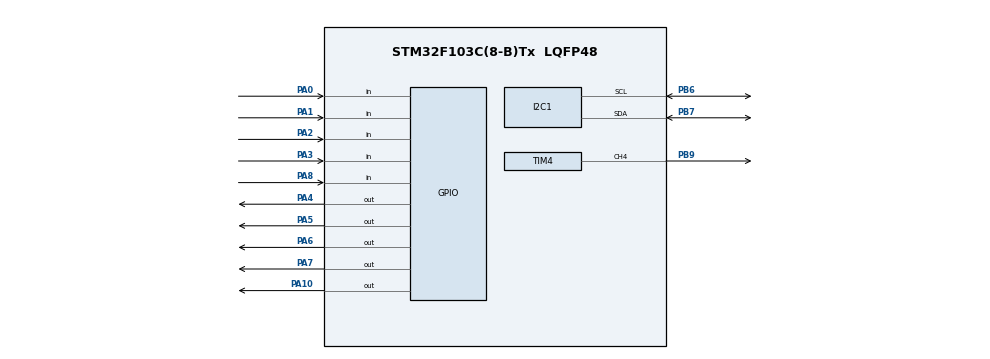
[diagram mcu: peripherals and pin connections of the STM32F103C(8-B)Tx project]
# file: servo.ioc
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I2C1.I2C_Mode=I2C_Fast
Mcu.Family=STM32F1
Mcu.Name=STM32F103C(8-B)Tx
Mcu.Package=LQFP48
NVIC.PriorityGroup=NVIC_PRIORITYGROUP_4
PA0-WKUP.GPIO_PuPd=GPIO_PULLDOWN
PA0-WKUP.Signal=GPIO_Input
PA1.GPIO_PuPd=GPIO_PULLDOWN
PA1.Signal=GPIO_Input
PA10.Signal=GPIO_Output
PA2.GPIO_PuPd=GPIO_PULLDOWN
PA2.Signal=GPIO_Input
PA3.GPIO_PuPd=GPIO_PULLDOWN
PA3.Signal=GPIO_Input
PA4.Signal=GPIO_Output
PA5.Signal=GPIO_Output
PA6.GPIO_ModeDefaultOutputPP=GPIO_MODE_OUTPUT_PP
PA6.Signal=GPIO_Output
PA7.Signal=GPIO_Output
PA8.GPIO_PuPd=GPIO_NOPULL
PA8.Signal=GPIO_Input
PB6.Mode=I2C
PB6.Signal=I2C1_SCL
PB7.Mode=I2C
PB7.Signal=I2C1_SDA
PB9.Signal=S_TIM4_CH4
ProjectManager.HeapSize=0x200
ProjectManager.StackSize=0x400
ProjectManager.TargetToolchain=MDK-ARM V5.32
RCC.APB1Freq_Value=8000000
RCC.APB2Freq_Value=8000000
SH.S_TIM4_CH4.0=TIM4_CH4,PWM Generation4 CH4
TIM4.Channel-PWM\ Generation4\ CH4=TIM_CHANNEL_4
TIM4.Period=19999
TIM4.Prescaler=7
VP_SYS_VS_ND.Mode=No_Debug
VP_TIM4_VS_ClockSourceINT.Mode=Internal
board=custom

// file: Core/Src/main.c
/* USER CODE BEGIN Header */
/* USER CODE END Header */
#include "main.h"

/* USER CODE BEGIN Includes */
#include "smart_door_lock.h"
/* USER CODE END Includes */

I2C_HandleTypeDef hi2c1;

TIM_HandleTypeDef htim4;

void SystemClock_Config(void);
static void MX_GPIO_Init(void);
static void MX_TIM4_Init(void);
static void MX_I2C1_Init(void);

int main(void)
{

  /* MCU Configuration--------------------------------------------------------*/

  /* Reset of all peripherals, Initializes the Flash interface and the Systick. */
  HAL_Init();

  /* Configure the system clock */
  SystemClock_Config();

  /* Initialize all configured peripherals */
  MX_GPIO_Init();
  MX_TIM4_Init();
  MX_I2C1_Init();
  /* USER CODE BEGIN 2 */

  /*  Initialize the Smart Door Lock system                     */
  /*  This sets up: OLED, PIR, Reed Switch, Buzzer, Servo, LEDs */
  /*------------------------------------------------------------*/
  SmartDoorLock_Init();

  /* USER CODE END 2 */

  /* Infinite loop */
  /* USER CODE BEGIN WHILE */
  while (1)
  {

    SmartDoorLock_Update();

    /* USER CODE END WHILE */

  }
}

void SystemClock_Config(void)
{
  RCC_OscInitTypeDef RCC_OscInitStruct = {0};
  RCC_ClkInitTypeDef RCC_ClkInitStruct = {0};

  /** Initializes the RCC Oscillators according to the specified parameters
  * in the RCC_OscInitTypeDef structure.
  */
  RCC_OscInitStruct.OscillatorType = RCC_OSCILLATORTYPE_HSI;
  RCC_OscInitStruct.HSIState = RCC_HSI_ON;
  RCC_OscInitStruct.HSICalibrationValue = RCC_HSICALIBRATION_DEFAULT;
  RCC_OscInitStruct.PLL.PLLState = RCC_PLL_NONE;
  if (HAL_RCC_OscConfig(&RCC_OscInitStruct) != HAL_OK)
  {
    Error_Handler();
  }

  /** Initializes the CPU, AHB and APB buses clocks
  */
  RCC_ClkInitStruct.ClockType = RCC_CLOCKTYPE_HCLK|RCC_CLOCKTYPE_SYSCLK
                              |RCC_CLOCKTYPE_PCLK1|RCC_CLOCKTYPE_PCLK2;
  RCC_ClkInitStruct.SYSCLKSource = RCC_SYSCLKSOURCE_HSI;
  RCC_ClkInitStruct.AHBCLKDivider = RCC_SYSCLK_DIV1;
  RCC_ClkInitStruct.APB1CLKDivider = RCC_HCLK_DIV1;
  RCC_ClkInitStruct.APB2CLKDivider = RCC_HCLK_DIV1;

  if (HAL_RCC_ClockConfig(&RCC_ClkInitStruct, FLASH_LATENCY_0) != HAL_OK)
  {
    Error_Handler();
  }
}

static void MX_I2C1_Init(void)
{

  hi2c1.Instance = I2C1;
  hi2c1.Init.ClockSpeed = 400000;
  hi2c1.Init.DutyCycle = I2C_DUTYCYCLE_2;
  hi2c1.Init.OwnAddress1 = 0;
  hi2c1.Init.AddressingMode = I2C_ADDRESSINGMODE_7BIT;
  hi2c1.Init.DualAddressMode = I2C_DUALADDRESS_DISABLE;
  hi2c1.Init.OwnAddress2 = 0;
  hi2c1.Init.GeneralCallMode = I2C_GENERALCALL_DISABLE;
  hi2c1.Init.NoStretchMode = I2C_NOSTRETCH_DISABLE;
  if (HAL_I2C_Init(&hi2c1) != HAL_OK)
  {
    Error_Handler();
  }

}

static void MX_TIM4_Init(void)
{

  TIM_ClockConfigTypeDef sClockSourceConfig = {0};
  TIM_MasterConfigTypeDef sMasterConfig = {0};
  TIM_OC_InitTypeDef sConfigOC = {0};

  htim4.Instance = TIM4;
  htim4.Init.Prescaler = 7;
  htim4.Init.CounterMode = TIM_COUNTERMODE_UP;
  htim4.Init.Period = 19999;
  htim4.Init.ClockDivision = TIM_CLOCKDIVISION_DIV1;
  htim4.Init.AutoReloadPreload = TIM_AUTORELOAD_PRELOAD_DISABLE;
  if (HAL_TIM_Base_Init(&htim4) != HAL_OK)
  {
    Error_Handler();
  }
  sClockSourceConfig.ClockSource = TIM_CLOCKSOURCE_INTERNAL;
  if (HAL_TIM_ConfigClockSource(&htim4, &sClockSourceConfig) != HAL_OK)
  {
    Error_Handler();
  }
  if (HAL_TIM_PWM_Init(&htim4) != HAL_OK)
  {
    Error_Handler();
  }
  sMasterConfig.MasterOutputTrigger = TIM_TRGO_RESET;
  sMasterConfig.MasterSlaveMode = TIM_MASTERSLAVEMODE_DISABLE;
  if (HAL_TIMEx_MasterConfigSynchronization(&htim4, &sMasterConfig) != HAL_OK)
  {
    Error_Handler();
  }
  sConfigOC.OCMode = TIM_OCMODE_PWM1;
  sConfigOC.Pulse = 0;
  sConfigOC.OCPolarity = TIM_OCPOLARITY_HIGH;
  sConfigOC.OCFastMode = TIM_OCFAST_DISABLE;
  if (HAL_TIM_PWM_ConfigChannel(&htim4, &sConfigOC, TIM_CHANNEL_4) != HAL_OK)
  {
    Error_Handler();
  }
  HAL_TIM_MspPostInit(&htim4);

}

static void MX_GPIO_Init(void)
{
  GPIO_InitTypeDef GPIO_InitStruct = {0};

  /* GPIO Ports Clock Enable */
  __HAL_RCC_GPIOA_CLK_ENABLE();
  __HAL_RCC_GPIOB_CLK_ENABLE();

  /*Configure GPIO pin Output Level */
  HAL_GPIO_WritePin(GPIOA, GPIO_PIN_4|GPIO_PIN_5|GPIO_PIN_6|GPIO_PIN_7
                          |GPIO_PIN_10, GPIO_PIN_RESET);

  /*Configure GPIO pins : PA0 PA1 PA2 PA3 */
  GPIO_InitStruct.Pin = GPIO_PIN_0|GPIO_PIN_1|GPIO_PIN_2|GPIO_PIN_3;
  GPIO_InitStruct.Mode = GPIO_MODE_INPUT;
  GPIO_InitStruct.Pull = GPIO_PULLDOWN;
  HAL_GPIO_Init(GPIOA, &GPIO_InitStruct);

  /*Configure GPIO pins : PA4 PA5 PA6 PA7
                           PA10 */
  GPIO_InitStruct.Pin = GPIO_PIN_4|GPIO_PIN_5|GPIO_PIN_6|GPIO_PIN_7
                          |GPIO_PIN_10;
  GPIO_InitStruct.Mode = GPIO_MODE_OUTPUT_PP;
  GPIO_InitStruct.Pull = GPIO_NOPULL;
  GPIO_InitStruct.Speed = GPIO_SPEED_FREQ_LOW;
  HAL_GPIO_Init(GPIOA, &GPIO_InitStruct);

  /*Configure GPIO pin : PA8 */
  GPIO_InitStruct.Pin = GPIO_PIN_8;
  GPIO_InitStruct.Mode = GPIO_MODE_INPUT;
  GPIO_InitStruct.Pull = GPIO_NOPULL;
  HAL_GPIO_Init(GPIOA, &GPIO_InitStruct);

}

void Error_Handler(void)
{
  __disable_irq();
  while (1)
  {
  }
}
